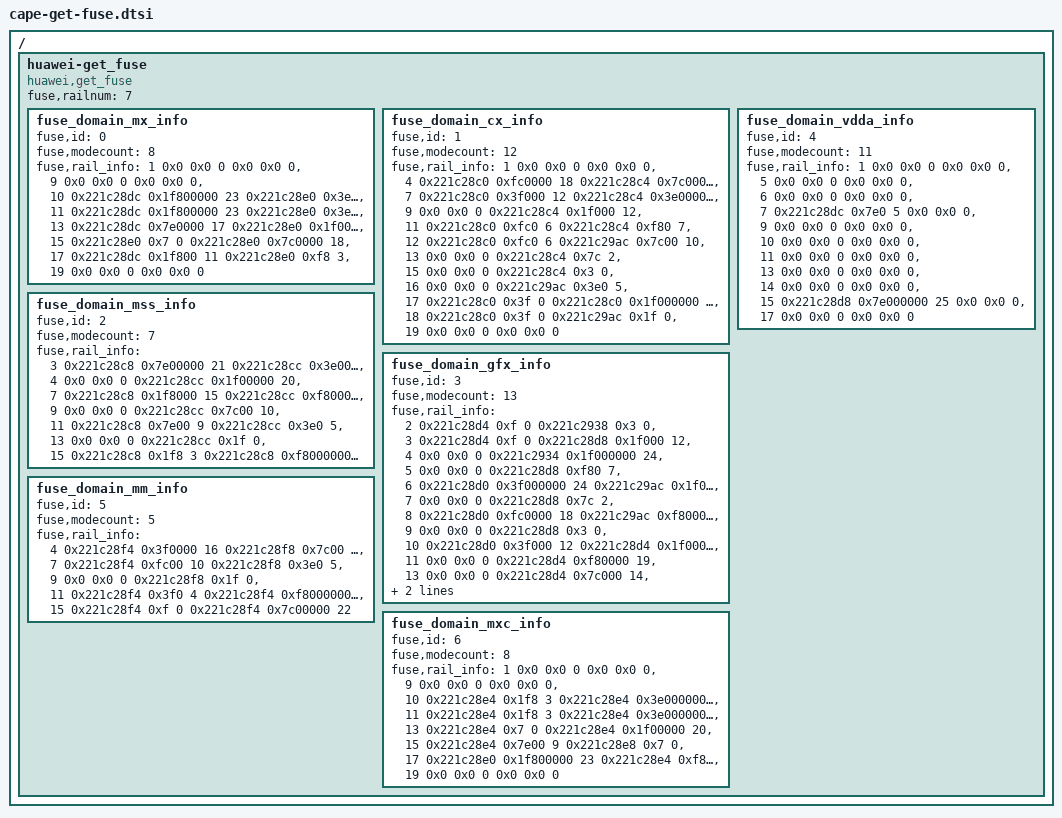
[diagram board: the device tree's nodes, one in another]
/ {
	huawei-get_fuse {
		compatible = "huawei,get_fuse";
		fuse,railnum = <7>;
		fuse_domain_mx_info {
			fuse,id = <0>;
			fuse,modecount = <8>;
			fuse,rail_info = <1 0x0 0x0 0 0x0 0x0 0>,
			                 <9 0x0 0x0 0 0x0 0x0 0>,
			                 <10 0x221c28dc 0x1f800000 23 0x221c28e0 0x3e000 13>,
			                 <11 0x221c28dc 0x1f800000 23 0x221c28e0 0x3e000 13>,
			                 <13 0x221c28dc 0x7e0000 17 0x221c28e0 0x1f00 8>,
			                 <15 0x221c28e0 0x7 0 0x221c28e0 0x7c0000 18>,
			                 <17 0x221c28dc 0x1f800 11 0x221c28e0 0xf8 3>,
			                 <19 0x0 0x0 0 0x0 0x0 0>;
		};
		fuse_domain_cx_info {
			fuse,id = <1>;
			fuse,modecount = <12>;
			fuse,rail_info = <1 0x0 0x0 0 0x0 0x0 0>,
			                 <4 0x221c28c0 0xfc0000 18 0x221c28c4 0x7c00000 22>,
			                 <7 0x221c28c0 0x3f000 12 0x221c28c4 0x3e0000 17>,
			                 <9 0x0 0x0 0 0x221c28c4 0x1f000 12>,
			                 <11 0x221c28c0 0xfc0 6 0x221c28c4 0xf80 7>,
			                 <12 0x221c28c0 0xfc0 6 0x221c29ac 0x7c00 10>,
			                 <13 0x0 0x0 0 0x221c28c4 0x7c 2>,
			                 <15 0x0 0x0 0 0x221c28c4 0x3 0>,
			                 <16 0x0 0x0 0 0x221c29ac 0x3e0 5>,
			                 <17 0x221c28c0 0x3f 0 0x221c28c0 0x1f000000 24>,
			                 <18 0x221c28c0 0x3f 0 0x221c29ac 0x1f 0>,
			                 <19 0x0 0x0 0 0x0 0x0 0>;
		};
		fuse_domain_mss_info {
			fuse,id = <2>;
			fuse,modecount = <7>;
			fuse,rail_info = <3 0x221c28c8 0x7e00000 21 0x221c28cc 0x3e000000 25>,
			                 <4 0x0 0x0 0 0x221c28cc 0x1f00000 20>,
			                 <7 0x221c28c8 0x1f8000 15 0x221c28cc 0xf8000 15>,
			                 <9 0x0 0x0 0 0x221c28cc 0x7c00 10>,
			                 <11 0x221c28c8 0x7e00 9 0x221c28cc 0x3e0 5>,
			                 <13 0x0 0x0 0 0x221c28cc 0x1f 0>,
			                 <15 0x221c28c8 0x1f8 3 0x221c28c8 0xf8000000 27>;
		};
		fuse_domain_gfx_info {
			fuse,id = <3>;
			fuse,modecount = <13>;
			fuse,rail_info = <2 0x221c28d4 0xf 0 0x221c2938 0x3 0>,
			                 <3 0x221c28d4 0xf 0 0x221c28d8 0x1f000 12>,
			                 <4 0x0 0x0 0 0x221c2934 0x1f000000 24>,
			                 <5 0x0 0x0 0 0x221c28d8 0xf80 7>,
			                 <6 0x221c28d0 0x3f000000 24 0x221c29ac 0x1f00000 20>,
			                 <7 0x0 0x0 0 0x221c28d8 0x7c 2>,
			                 <8 0x221c28d0 0xfc0000 18 0x221c29ac 0xf8000 15>,
			                 <9 0x0 0x0 0 0x221c28d8 0x3 0>,
			                 <10 0x221c28d0 0x3f000 12 0x221c28d4 0x1f000000 24>,
			                 <11 0x0 0x0 0 0x221c28d4 0xf80000 19>,
			                 <13 0x0 0x0 0 0x221c28d4 0x7c000 14>,
			                 <15 0x0 0x0 0 0x221c28d4 0x3e00 9>,
			                 <17 0x221c28d0 0xfc0 6 0x221c28d4 0x1f0 4>;
		};
		fuse_domain_vdda_info {
			fuse,id = <4>;
			fuse,modecount = <11>;
			fuse,rail_info = <1 0x0 0x0 0 0x0 0x0 0>,
			                 <5 0x0 0x0 0 0x0 0x0 0>,
			                 <6 0x0 0x0 0 0x0 0x0 0>,
			                 <7 0x221c28dc 0x7e0 5 0x0 0x0 0>,
			                 <9 0x0 0x0 0 0x0 0x0 0>,
			                 <10 0x0 0x0 0 0x0 0x0 0>,
			                 <11 0x0 0x0 0 0x0 0x0 0>,
			                 <13 0x0 0x0 0 0x0 0x0 0>,
			                 <14 0x0 0x0 0 0x0 0x0 0>,
			                 <15 0x221c28d8 0x7e000000 25 0x0 0x0 0>,
			                 <17 0x0 0x0 0 0x0 0x0 0>;
		};
		fuse_domain_mm_info {
			fuse,id = <5>;
			fuse,modecount = <5>;
			fuse,rail_info = <4 0x221c28f4 0x3f0000 16 0x221c28f8 0x7c00 10>,
			                 <7 0x221c28f4 0xfc00 10 0x221c28f8 0x3e0 5>,
			                 <9 0x0 0x0 0 0x221c28f8 0x1f 0>,
			                 <11 0x221c28f4 0x3f0 4 0x221c28f4 0xf8000000 27>,
			                 <15 0x221c28f4 0xf 0 0x221c28f4 0x7c00000 22>;
		};
		fuse_domain_mxc_info {
			fuse,id = <6>;
			fuse,modecount = <8>;
			fuse,rail_info = <1 0x0 0x0 0 0x0 0x0 0>,
			                 <9 0x0 0x0 0 0x0 0x0 0>,
			                 <10 0x221c28e4 0x1f8 3 0x221c28e4 0x3e000000 25>,
			                 <11 0x221c28e4 0x1f8 3 0x221c28e4 0x3e000000 25>,
			                 <13 0x221c28e4 0x7 0 0x221c28e4 0x1f00000 20>,
			                 <15 0x221c28e4 0x7e00 9 0x221c28e8 0x7 0>,
			                 <17 0x221c28e0 0x1f800000 23 0x221c28e4 0xf8000 15>,
			                 <19 0x0 0x0 0 0x0 0x0 0>;
		};
	};
};
